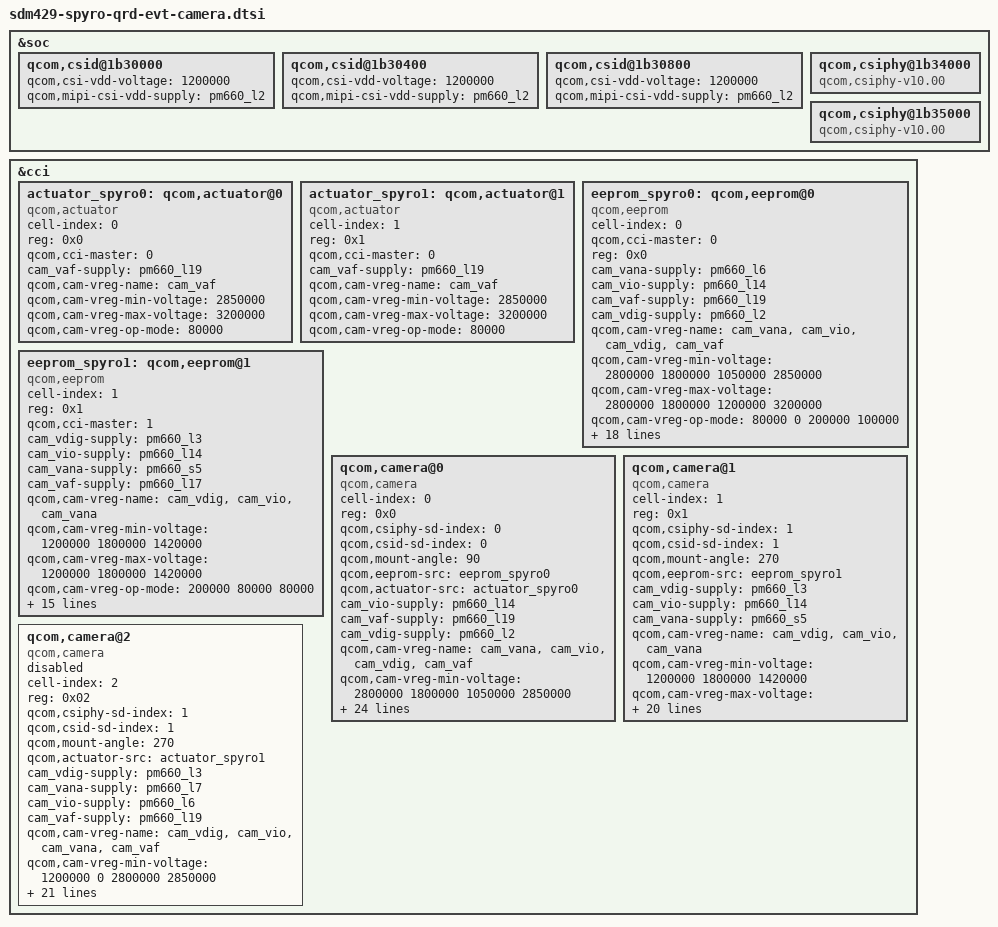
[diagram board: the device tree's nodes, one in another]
/*
 * Copyright (c) 2020 The Linux Foundation. All rights reserved.
 *
 * This program is free software; you can redistribute it and/or modify
 * it under the terms of the GNU General Public License version 2 and
 * only version 2 as published by the Free Software Foundation.
 *
 * This program is distributed in the hope that it will be useful,
 * but WITHOUT ANY WARRANTY; without even the implied warranty of
 * MERCHANTABILITY or FITNESS FOR A PARTICULAR PURPOSE.  See the
 * GNU General Public License for more details.
 */

#include <dt-bindings/clock/qcom,gcc-sdm429w.h>
#include <dt-bindings/clock/qcom,cpu-sdm.h>

&soc {
	qcom,csid@1b30000 {
		qcom,csi-vdd-voltage = <1200000>;
		qcom,mipi-csi-vdd-supply = <&pm660_l2>;
	};

	qcom,csid@1b30400 {
		qcom,csi-vdd-voltage = <1200000>;
		qcom,mipi-csi-vdd-supply = <&pm660_l2>;
	};
	qcom,csid@1b30800 {
		qcom,csi-vdd-voltage = <1200000>;
		qcom,mipi-csi-vdd-supply = <&pm660_l2>;
	};
	qcom,csiphy@1b34000 {
		compatible = "qcom,csiphy-v10.00", "qcom,csiphy";
	};
	qcom,csiphy@1b35000 {
		compatible = "qcom,csiphy-v10.00", "qcom,csiphy";
	};
};

&cci {
	#address-cells = <1>;
	#size-cells = <0>;

	actuator_spyro0: qcom,actuator@0 {
		cell-index = <0>;
		reg = <0x0>;
		compatible = "qcom,actuator";
		qcom,cci-master = <0>;
		cam_vaf-supply = <&pm660_l19>;
		qcom,cam-vreg-name = "cam_vaf";
		qcom,cam-vreg-min-voltage = <2850000>;
		qcom,cam-vreg-max-voltage = <3200000>;
		qcom,cam-vreg-op-mode = <80000>;
	};

	actuator_spyro1: qcom,actuator@1 {
		cell-index = <1>;
		reg = <0x1>;
		compatible = "qcom,actuator";
		qcom,cci-master = <0>;
		cam_vaf-supply = <&pm660_l19>;
		qcom,cam-vreg-name = "cam_vaf";
		qcom,cam-vreg-min-voltage = <2850000>;
		qcom,cam-vreg-max-voltage = <3200000>;
		qcom,cam-vreg-op-mode = <80000>;
	};

	eeprom_spyro0: qcom,eeprom@0 {
		cell-index = <0>;
		compatible = "qcom,eeprom";
		qcom,cci-master = <0>;
		reg = <0x0>;
		cam_vana-supply = <&pm660_l6>;
		cam_vio-supply = <&pm660_l14>;
		cam_vaf-supply = <&pm660_l19>;
		cam_vdig-supply = <&pm660_l2>;
		qcom,cam-vreg-name = "cam_vana", "cam_vio",
					"cam_vdig", "cam_vaf";
		qcom,cam-vreg-min-voltage = <2800000 1800000 1050000 2850000>;
		qcom,cam-vreg-max-voltage = <2800000 1800000 1200000 3200000>;
		qcom,cam-vreg-op-mode = <80000 0 200000 100000>;
		pinctrl-names = "cam_default", "cam_suspend";
		pinctrl-0 = <&cam_sensor_mclk0_default
				&cam_sensor_rear_reset
				&cam_sensor_rear_vana
				&cam_sensor_rear_standby>;
		pinctrl-1 = <&cam_sensor_mclk0_sleep
				&cam_sensor_rear_reset_sleep
				&cam_sensor_rear_vana_sleep
				&cam_sensor_rear_standby_sleep>;
		gpios = <&tlmm 26 0>,
			<&tlmm 36 0>,
			<&tlmm 58 0>,
			<&tlmm 92 0>;
		qcom,gpio-reset = <1>;
		qcom,gpio-vana = <2>;
		qcom,gpio-standby = <3>;
		qcom,gpio-req-tbl-num = <0 1 2 3>;
		qcom,gpio-req-tbl-flags = <1 0 0 0>;
		qcom,gpio-req-tbl-label = "CAMIF_MCLK0",
			"CAM_RESET0",
			"CAM_VANA",
			"CAM_STANDBY";
		status = "ok";
		clocks = <&gcc MCLK0_CLK_SRC>,
			<&gcc GCC_CAMSS_MCLK0_CLK>;
		clock-names = "cam_src_clk", "cam_clk";
		qcom,clock-rates = <19200000 0>;
	};

	eeprom_spyro1: qcom,eeprom@1 {
		cell-index = <1>;
		reg = <0x1>;
		compatible = "qcom,eeprom";
		qcom,cci-master = <1>;

		cam_vdig-supply = <&pm660_l3>;
		cam_vio-supply = <&pm660_l14>;
		cam_vana-supply = <&pm660_s5>;
		cam_vaf-supply = <&pm660_l17>;
		qcom,cam-vreg-name = "cam_vdig", "cam_vio", "cam_vana";
		qcom,cam-vreg-min-voltage = <1200000 1800000 1420000>;
		qcom,cam-vreg-max-voltage = <1200000 1800000 1420000>;
		qcom,cam-vreg-op-mode = <200000 80000 80000>;
		pinctrl-names = "cam_default", "cam_suspend";
		pinctrl-0 = <&cam_sensor_mclk1_default
			&cam_sensor_front_default>;
		pinctrl-1 = <&cam_sensor_mclk1_sleep
			&cam_sensor_front_sleep>;
		gpios = <&tlmm 27 0>,
			<&tlmm 33 0>,
			<&tlmm 66 0>,
			<&tlmm 38 0>;
		qcom,gpio-vana= <1>;
		qcom,gpio-vdig= <2>;
		qcom,gpio-reset = <3>;
		qcom,gpio-req-tbl-num = <0 1 2 3>;
		qcom,gpio-req-tbl-flags = <1 0 0 0>;
		qcom,gpio-req-tbl-label = "CAMIF_MCLK1",
								"CAM_AVDD1",
								"CAM_DVDD1",
								"CAM_RESET1";
		status = "ok";
		clocks = <&gcc MCLK1_CLK_SRC>,
					<&gcc GCC_CAMSS_MCLK1_CLK>;
		clock-names = "cam_src_clk", "cam_clk";
		qcom,clock-rates = <24000000 0>;
	};

	qcom,camera@0 {
		cell-index = <0>;
		compatible = "qcom,camera";
		reg = <0x0>;
		qcom,csiphy-sd-index = <0>;
		qcom,csid-sd-index = <0>;
		qcom,mount-angle = <90>;
		qcom,eeprom-src = <&eeprom_spyro0>;
		qcom,actuator-src = <&actuator_spyro0>;
		cam_vio-supply = <&pm660_l14>;
		cam_vaf-supply = <&pm660_l19>;
		cam_vdig-supply = <&pm660_l2>;
		qcom,cam-vreg-name = "cam_vana", "cam_vio",
				"cam_vdig", "cam_vaf";
		qcom,cam-vreg-min-voltage = <2800000 1800000 1050000 2850000>;
		qcom,cam-vreg-max-voltage = <2800000 1800000 1200000 3200000>;
		qcom,cam-vreg-op-mode = <80000 0 200000 100000>;
		pinctrl-names = "cam_default", "cam_suspend";
		pinctrl-0 = <&cam_sensor_mclk0_default
				&cam_sensor_rear_reset
				&cam_sensor_rear_vana
				&cam_sensor_rear_standby>;
		pinctrl-1 = <&cam_sensor_mclk0_sleep
				&cam_sensor_rear_reset_sleep
				&cam_sensor_rear_vana_sleep
				&cam_sensor_rear_standby_sleep>;
		gpios = <&tlmm 26 0>,
			<&tlmm 36 0>,
			<&tlmm 58 0>,
			<&tlmm 92 0>;
		qcom,gpio-reset = <1>;
		qcom,gpio-vana = <2>;
		qcom,gpio-standby = <3>;
		qcom,gpio-req-tbl-num = <0 1 2 3>;
		qcom,gpio-req-tbl-flags = <1 0 0 0>;
		qcom,gpio-req-tbl-label = "CAMIF_MCLK0",
								"CAM_RESET0",
								"CAM_VANA",
								"CAM_STANDBY";
		qcom,sensor-position = <0>;
		qcom,sensor-mode = <0>;
		qcom,cci-master = <0>;
		status = "ok";
		clocks = <&gcc MCLK0_CLK_SRC>,
					<&gcc GCC_CAMSS_MCLK0_CLK>;
		clock-names = "cam_src_clk", "cam_clk";
		qcom,clock-rates = <24000000 0>;
	};

	qcom,camera@1 {
		cell-index = <1>;
		compatible = "qcom,camera";
		reg = <0x1>;
		qcom,csiphy-sd-index = <1>;
		qcom,csid-sd-index = <1>;
		qcom,mount-angle = <270>;
		qcom,eeprom-src = <&eeprom_spyro1>;

		cam_vdig-supply = <&pm660_l3>;
		cam_vio-supply = <&pm660_l14>;
		cam_vana-supply = <&pm660_s5>;
		qcom,cam-vreg-name = "cam_vdig", "cam_vio", "cam_vana";
		qcom,cam-vreg-min-voltage = <1200000 1800000 1420000>;
		qcom,cam-vreg-max-voltage = <1200000 1800000 1420000>;
		qcom,cam-vreg-op-mode = <200000 80000 80000>;
		pinctrl-names = "cam_default", "cam_suspend";
		pinctrl-0 = <&cam_sensor_mclk1_default
				&cam_sensor_front_default>;
		pinctrl-1 = <&cam_sensor_mclk1_sleep
				&cam_sensor_front_sleep>;
		gpios = <&tlmm 27 0>,
			<&tlmm 33 0>,
			<&tlmm 66 0>,
			<&tlmm 38 0>;
		qcom,gpio-vana= <1>;
		qcom,gpio-vdig= <2>;
		qcom,gpio-reset = <3>;
		qcom,gpio-req-tbl-num = <0 1 2 3>;
		qcom,gpio-req-tbl-flags = <1 0 0 0>;
		qcom,gpio-req-tbl-label = "CAMIF_MCLK1",
								"CAM_AVDD1",
								"CAM_DVDD1",
								"CAM_RESET1";
		qcom,sensor-position = <0x1>;
		qcom,sensor-mode = <0>;
		qcom,cci-master = <1>;
		clocks = <&gcc MCLK1_CLK_SRC>,
					<&gcc GCC_CAMSS_MCLK1_CLK>;
		clock-names = "cam_src_clk", "cam_clk";
		qcom,clock-rates = <24000000 0>;
	};

	qcom,camera@2 {
		cell-index = <2>;
		compatible = "qcom,camera";
		reg = <0x02>;
		qcom,csiphy-sd-index = <1>;
		qcom,csid-sd-index = <1>;
		qcom,mount-angle = <270>;
		qcom,actuator-src = <&actuator_spyro1>;
		cam_vdig-supply = <&pm660_l3>;
		cam_vana-supply = <&pm660_l7>;
		cam_vio-supply = <&pm660_l6>;
		cam_vaf-supply = <&pm660_l19>;
		qcom,cam-vreg-name = "cam_vdig", "cam_vio", "cam_vana",
					"cam_vaf";
		qcom,cam-vreg-min-voltage = <1200000 0 2800000 2850000>;
		qcom,cam-vreg-max-voltage = <1200000 0 2800000 3200000>;
		qcom,cam-vreg-op-mode = <105000 0 80000 100000>;
		qcom,gpio-no-mux = <0>;
		pinctrl-names = "cam_default", "cam_suspend";
		pinctrl-0 = <&cam_sensor_mclk2_default
				&cam_sensor_front1_default>;
		pinctrl-1 = <&cam_sensor_mclk2_sleep
				&cam_sensor_front1_sleep>;
		gpios = <&tlmm 27 0>,
			<&tlmm 38 0>,
			<&tlmm 39 0>;
		qcom,gpio-reset = <1>;
		qcom,gpio-standby = <2>;
		qcom,gpio-req-tbl-num = <0 1 2>;
		qcom,gpio-req-tbl-flags = <1 0 0>;
		qcom,gpio-req-tbl-label = "CAMIF_MCLK2",
					  "CAM_RESET2",
					  "CAM_STANDBY2";
		qcom,sensor-position = <1>;
		qcom,sensor-mode = <0>;
		qcom,cci-master = <0>;
		status = "disabled";
		clocks = <&gcc MCLK2_CLK_SRC>,
			<&gcc GCC_CAMSS_MCLK2_CLK>;
		clock-names = "cam_src_clk", "cam_clk";
		qcom,clock-rates = <24000000 0>;
	};
};
